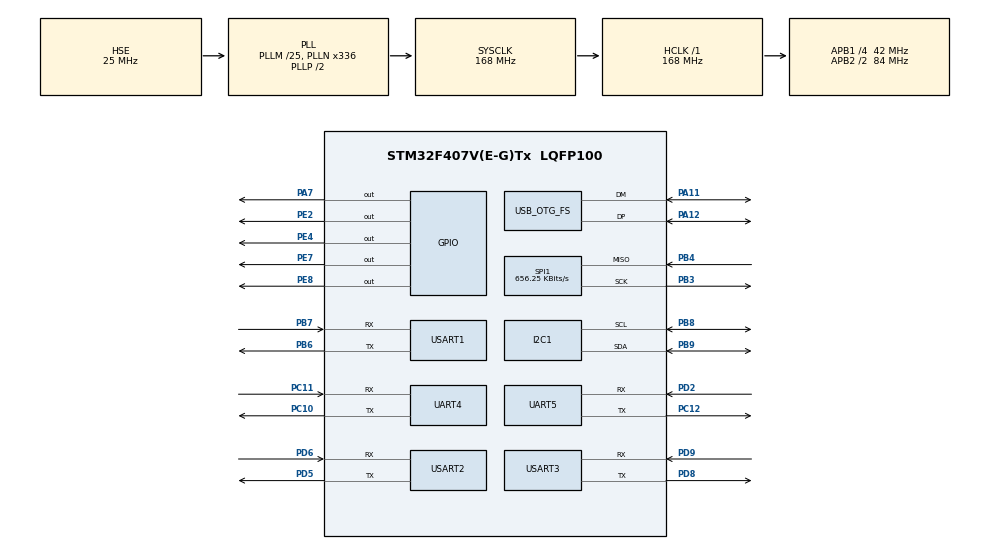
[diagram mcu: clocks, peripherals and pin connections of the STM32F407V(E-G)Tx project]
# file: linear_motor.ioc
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Mcu.Family=STM32F4
Mcu.Name=STM32F407V(E-G)Tx
Mcu.Package=LQFP100
NVIC.OTG_FS_IRQn=true\:0\:0\:false\:false\:true\:false\:true
NVIC.PriorityGroup=NVIC_PRIORITYGROUP_4
NVIC.TIM7_IRQn=true\:0\:0\:false\:false\:true\:true\:true
NVIC.UART4_IRQn=true\:0\:0\:false\:false\:true\:true\:true
NVIC.USART2_IRQn=true\:0\:0\:false\:false\:true\:true\:true
NVIC.USART3_IRQn=true\:0\:0\:false\:false\:true\:true\:true
PA11.Mode=Device_Only
PA11.Signal=USB_OTG_FS_DM
PA12.Mode=Device_Only
PA12.Signal=USB_OTG_FS_DP
PA7.Signal=GPIO_Output
PB3.Mode=RX_Only_Simplex_Unidirect_Master
PB3.Signal=SPI1_SCK
PB4.Mode=RX_Only_Simplex_Unidirect_Master
PB4.Signal=SPI1_MISO
PB6.Mode=Asynchronous
PB6.Signal=USART1_TX
PB7.Mode=Asynchronous
PB7.Signal=USART1_RX
PB8.Mode=I2C
PB8.Signal=I2C1_SCL
PB9.Mode=I2C
PB9.Signal=I2C1_SDA
PC10.Mode=Asynchronous
PC10.Signal=UART4_TX
PC11.Mode=Asynchronous
PC11.Signal=UART4_RX
PC12.Mode=Asynchronous
PC12.Signal=UART5_TX
PD2.Mode=Asynchronous
PD2.Signal=UART5_RX
PD5.Mode=Asynchronous
PD5.Signal=USART2_TX
PD6.GPIO_PuPd=GPIO_PULLUP
PD6.Mode=Asynchronous
PD6.Signal=USART2_RX
PD8.Mode=Asynchronous
PD8.Signal=USART3_TX
PD9.Mode=Asynchronous
PD9.Signal=USART3_RX
PE2.Signal=GPIO_Output
PE4.Signal=GPIO_Output
PE7.Signal=GPIO_Output
PE8.Signal=GPIO_Output
PH0-OSC_IN.Mode=HSE-External-Oscillator
PH0-OSC_IN.Signal=RCC_OSC_IN
PH1-OSC_OUT.Mode=HSE-External-Oscillator
PH1-OSC_OUT.Signal=RCC_OSC_OUT
ProjectManager.HeapSize=0x200
ProjectManager.StackSize=0x400
ProjectManager.TargetToolchain=STM32CubeIDE
RCC.48MHZClocksFreq_Value=48000000
RCC.AHBFreq_Value=168000000
RCC.APB1CLKDivider=RCC_HCLK_DIV4
RCC.APB1Freq_Value=42000000
RCC.APB1TimFreq_Value=84000000
RCC.APB2CLKDivider=RCC_HCLK_DIV2
RCC.APB2Freq_Value=84000000
RCC.APB2TimFreq_Value=168000000
RCC.CortexFreq_Value=168000000
RCC.EnbaleCSS=true
RCC.HCLKFreq_Value=168000000
RCC.HSE_VALUE=25000000
RCC.HSI_VALUE=16000000
RCC.LSE_VALUE=32768
RCC.PLLM=25
RCC.PLLN=336
RCC.PLLQ=7
RCC.SYSCLKFreq_VALUE=168000000
RCC.SYSCLKSource=RCC_SYSCLKSOURCE_PLLCLK
RCC.VCOOutputFreq_Value=336000000
SPI1.BaudRatePrescaler=SPI_BAUDRATEPRESCALER_128
SPI1.CalculateBaudRate=656.25 KBits/s
SPI1.Direction=SPI_DIRECTION_2LINES_RXONLY
SPI1.Mode=SPI_MODE_MASTER
SPI1.VirtualType=VM_MASTER
TIM7.Period=999
TIM7.Prescaler=2099
UART4.VirtualMode=Asynchronous
UART5.VirtualMode=Asynchronous
USART1.Parity=PARITY_EVEN
USART1.VirtualMode=VM_ASYNC
USART1.WordLength=WORDLENGTH_9B
USART2.VirtualMode=VM_ASYNC
USART3.VirtualMode=VM_ASYNC
USB_DEVICE.CLASS_NAME_FS=CDC
USB_DEVICE.MANUFACTURER_STRING-CDC_FS=Cytena BPS
USB_DEVICE.PRODUCT_STRING_CDC_FS=CYTENABPS_SNEST
USB_DEVICE.VirtualMode-CDC_FS=Cdc
USB_DEVICE.VirtualModeFS=Cdc_FS
USB_OTG_FS.VirtualMode=Device_Only
VP_TIM7_VS_ClockSourceINT.Mode=Enable_Timer
VP_USB_DEVICE_VS_USB_DEVICE_CDC_FS.Mode=CDC_FS
board=custom

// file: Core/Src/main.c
/* USER CODE BEGIN Header */
/**
  ******************************************************************************
  * @file           : main.c
  * @brief          : Main program body
  ******************************************************************************
  * @attention
  *
  * <h2><center>&copy; Copyright (c) 2022 STMicroelectronics.
  * All rights reserved.</center></h2>
  *
  * This software component is licensed by ST under Ultimate Liberty license
  * SLA0044, the "License"; You may not use this file except in compliance with
  * the License. You may obtain a copy of the License at:
  *                             www.st.com/SLA0044
  *
  ******************************************************************************
  */
/* USER CODE END Header */
#include "main.h"
#include "usb_device.h"

/* USER CODE BEGIN Includes */
#include "user_main.hpp"
/* USER CODE END Includes */

I2C_HandleTypeDef hi2c1;

SPI_HandleTypeDef hspi1;

TIM_HandleTypeDef htim7;

UART_HandleTypeDef huart4;
UART_HandleTypeDef huart5;
UART_HandleTypeDef huart1;
UART_HandleTypeDef huart2;
UART_HandleTypeDef huart3;

void SystemClock_Config(void);
static void MX_GPIO_Init(void);
static void MX_UART4_Init(void);
static void MX_USART3_UART_Init(void);
static void MX_I2C1_Init(void);
static void MX_SPI1_Init(void);
static void MX_USART1_UART_Init(void);
static void MX_USART2_UART_Init(void);
static void MX_TIM7_Init(void);
static void MX_UART5_Init(void);

int main(void)
{

  /* MCU Configuration--------------------------------------------------------*/

  /* Reset of all peripherals, Initializes the Flash interface and the Systick. */
  HAL_Init();

  /* Configure the system clock */
  SystemClock_Config();

  /* Initialize all configured peripherals */
  MX_GPIO_Init();
  MX_UART4_Init();
  MX_USB_DEVICE_Init();
  MX_USART3_UART_Init();
  MX_I2C1_Init();
  MX_SPI1_Init();
  MX_USART1_UART_Init();
  MX_USART2_UART_Init();
  MX_TIM7_Init();
  MX_UART5_Init();
  /* USER CODE BEGIN 2 */
  user_init();
  /* USER CODE END 2 */

  /* Infinite loop */
  /* USER CODE BEGIN WHILE */
  while (1)
  {
	  user_main();
    /* USER CODE END WHILE */

  }
}

void SystemClock_Config(void)
{
  RCC_OscInitTypeDef RCC_OscInitStruct = {0};
  RCC_ClkInitTypeDef RCC_ClkInitStruct = {0};

  /** Configure the main internal regulator output voltage
  */
  __HAL_RCC_PWR_CLK_ENABLE();
  __HAL_PWR_VOLTAGESCALING_CONFIG(PWR_REGULATOR_VOLTAGE_SCALE1);
  /** Initializes the RCC Oscillators according to the specified parameters
  * in the RCC_OscInitTypeDef structure.
  */
  RCC_OscInitStruct.OscillatorType = RCC_OSCILLATORTYPE_HSE;
  RCC_OscInitStruct.HSEState = RCC_HSE_ON;
  RCC_OscInitStruct.PLL.PLLState = RCC_PLL_ON;
  RCC_OscInitStruct.PLL.PLLSource = RCC_PLLSOURCE_HSE;
  RCC_OscInitStruct.PLL.PLLM = 25;
  RCC_OscInitStruct.PLL.PLLN = 336;
  RCC_OscInitStruct.PLL.PLLP = RCC_PLLP_DIV2;
  RCC_OscInitStruct.PLL.PLLQ = 7;
  if (HAL_RCC_OscConfig(&RCC_OscInitStruct) != HAL_OK)
  {
    Error_Handler();
  }
  /** Initializes the CPU, AHB and APB buses clocks
  */
  RCC_ClkInitStruct.ClockType = RCC_CLOCKTYPE_HCLK|RCC_CLOCKTYPE_SYSCLK
                              |RCC_CLOCKTYPE_PCLK1|RCC_CLOCKTYPE_PCLK2;
  RCC_ClkInitStruct.SYSCLKSource = RCC_SYSCLKSOURCE_PLLCLK;
  RCC_ClkInitStruct.AHBCLKDivider = RCC_SYSCLK_DIV1;
  RCC_ClkInitStruct.APB1CLKDivider = RCC_HCLK_DIV4;
  RCC_ClkInitStruct.APB2CLKDivider = RCC_HCLK_DIV2;

  if (HAL_RCC_ClockConfig(&RCC_ClkInitStruct, FLASH_LATENCY_5) != HAL_OK)
  {
    Error_Handler();
  }
  /** Enables the Clock Security System
  */
  HAL_RCC_EnableCSS();
}

static void MX_I2C1_Init(void)
{

  hi2c1.Instance = I2C1;
  hi2c1.Init.ClockSpeed = 100000;
  hi2c1.Init.DutyCycle = I2C_DUTYCYCLE_2;
  hi2c1.Init.OwnAddress1 = 0;
  hi2c1.Init.AddressingMode = I2C_ADDRESSINGMODE_7BIT;
  hi2c1.Init.DualAddressMode = I2C_DUALADDRESS_DISABLE;
  hi2c1.Init.OwnAddress2 = 0;
  hi2c1.Init.GeneralCallMode = I2C_GENERALCALL_DISABLE;
  hi2c1.Init.NoStretchMode = I2C_NOSTRETCH_DISABLE;
  if (HAL_I2C_Init(&hi2c1) != HAL_OK)
  {
    Error_Handler();
  }

}

static void MX_SPI1_Init(void)
{

  /* SPI1 parameter configuration*/
  hspi1.Instance = SPI1;
  hspi1.Init.Mode = SPI_MODE_MASTER;
  hspi1.Init.Direction = SPI_DIRECTION_2LINES_RXONLY;
  hspi1.Init.DataSize = SPI_DATASIZE_8BIT;
  hspi1.Init.CLKPolarity = SPI_POLARITY_LOW;
  hspi1.Init.CLKPhase = SPI_PHASE_1EDGE;
  hspi1.Init.NSS = SPI_NSS_SOFT;
  hspi1.Init.BaudRatePrescaler = SPI_BAUDRATEPRESCALER_128;
  hspi1.Init.FirstBit = SPI_FIRSTBIT_MSB;
  hspi1.Init.TIMode = SPI_TIMODE_DISABLE;
  hspi1.Init.CRCCalculation = SPI_CRCCALCULATION_DISABLE;
  hspi1.Init.CRCPolynomial = 10;
  if (HAL_SPI_Init(&hspi1) != HAL_OK)
  {
    Error_Handler();
  }

}

static void MX_TIM7_Init(void)
{

  TIM_MasterConfigTypeDef sMasterConfig = {0};

  htim7.Instance = TIM7;
  htim7.Init.Prescaler = 2099;
  htim7.Init.CounterMode = TIM_COUNTERMODE_UP;
  htim7.Init.Period = 999;
  htim7.Init.AutoReloadPreload = TIM_AUTORELOAD_PRELOAD_DISABLE;
  if (HAL_TIM_Base_Init(&htim7) != HAL_OK)
  {
    Error_Handler();
  }
  sMasterConfig.MasterOutputTrigger = TIM_TRGO_RESET;
  sMasterConfig.MasterSlaveMode = TIM_MASTERSLAVEMODE_DISABLE;
  if (HAL_TIMEx_MasterConfigSynchronization(&htim7, &sMasterConfig) != HAL_OK)
  {
    Error_Handler();
  }

}

static void MX_UART4_Init(void)
{

  huart4.Instance = UART4;
  huart4.Init.BaudRate = 115200;
  huart4.Init.WordLength = UART_WORDLENGTH_8B;
  huart4.Init.StopBits = UART_STOPBITS_1;
  huart4.Init.Parity = UART_PARITY_NONE;
  huart4.Init.Mode = UART_MODE_TX_RX;
  huart4.Init.HwFlowCtl = UART_HWCONTROL_NONE;
  huart4.Init.OverSampling = UART_OVERSAMPLING_16;
  if (HAL_UART_Init(&huart4) != HAL_OK)
  {
    Error_Handler();
  }

}

static void MX_UART5_Init(void)
{

  huart5.Instance = UART5;
  huart5.Init.BaudRate = 115200;
  huart5.Init.WordLength = UART_WORDLENGTH_8B;
  huart5.Init.StopBits = UART_STOPBITS_1;
  huart5.Init.Parity = UART_PARITY_NONE;
  huart5.Init.Mode = UART_MODE_TX_RX;
  huart5.Init.HwFlowCtl = UART_HWCONTROL_NONE;
  huart5.Init.OverSampling = UART_OVERSAMPLING_16;
  if (HAL_UART_Init(&huart5) != HAL_OK)
  {
    Error_Handler();
  }

}

static void MX_USART1_UART_Init(void)
{

  huart1.Instance = USART1;
  huart1.Init.BaudRate = 115200;
  huart1.Init.WordLength = UART_WORDLENGTH_9B;
  huart1.Init.StopBits = UART_STOPBITS_1;
  huart1.Init.Parity = UART_PARITY_EVEN;
  huart1.Init.Mode = UART_MODE_TX_RX;
  huart1.Init.HwFlowCtl = UART_HWCONTROL_NONE;
  huart1.Init.OverSampling = UART_OVERSAMPLING_16;
  if (HAL_UART_Init(&huart1) != HAL_OK)
  {
    Error_Handler();
  }

}

static void MX_USART2_UART_Init(void)
{

  huart2.Instance = USART2;
  huart2.Init.BaudRate = 115200;
  huart2.Init.WordLength = UART_WORDLENGTH_8B;
  huart2.Init.StopBits = UART_STOPBITS_1;
  huart2.Init.Parity = UART_PARITY_NONE;
  huart2.Init.Mode = UART_MODE_TX_RX;
  huart2.Init.HwFlowCtl = UART_HWCONTROL_NONE;
  huart2.Init.OverSampling = UART_OVERSAMPLING_16;
  if (HAL_UART_Init(&huart2) != HAL_OK)
  {
    Error_Handler();
  }

}

static void MX_USART3_UART_Init(void)
{

  huart3.Instance = USART3;
  huart3.Init.BaudRate = 115200;
  huart3.Init.WordLength = UART_WORDLENGTH_8B;
  huart3.Init.StopBits = UART_STOPBITS_1;
  huart3.Init.Parity = UART_PARITY_NONE;
  huart3.Init.Mode = UART_MODE_TX_RX;
  huart3.Init.HwFlowCtl = UART_HWCONTROL_NONE;
  huart3.Init.OverSampling = UART_OVERSAMPLING_16;
  if (HAL_UART_Init(&huart3) != HAL_OK)
  {
    Error_Handler();
  }

}

static void MX_GPIO_Init(void)
{
  GPIO_InitTypeDef GPIO_InitStruct = {0};

  /* GPIO Ports Clock Enable */
  __HAL_RCC_GPIOE_CLK_ENABLE();
  __HAL_RCC_GPIOH_CLK_ENABLE();
  __HAL_RCC_GPIOA_CLK_ENABLE();
  __HAL_RCC_GPIOD_CLK_ENABLE();
  __HAL_RCC_GPIOC_CLK_ENABLE();
  __HAL_RCC_GPIOB_CLK_ENABLE();

  /*Configure GPIO pin Output Level */
  HAL_GPIO_WritePin(GPIOE, GPIO_PIN_2|GPIO_PIN_4|GPIO_PIN_7|GPIO_PIN_8, GPIO_PIN_RESET);

  /*Configure GPIO pin Output Level */
  HAL_GPIO_WritePin(GPIOA, GPIO_PIN_7, GPIO_PIN_RESET);

  /*Configure GPIO pins : PE2 PE4 PE7 PE8 */
  GPIO_InitStruct.Pin = GPIO_PIN_2|GPIO_PIN_4|GPIO_PIN_7|GPIO_PIN_8;
  GPIO_InitStruct.Mode = GPIO_MODE_OUTPUT_PP;
  GPIO_InitStruct.Pull = GPIO_NOPULL;
  GPIO_InitStruct.Speed = GPIO_SPEED_FREQ_LOW;
  HAL_GPIO_Init(GPIOE, &GPIO_InitStruct);

  /*Configure GPIO pin : PA7 */
  GPIO_InitStruct.Pin = GPIO_PIN_7;
  GPIO_InitStruct.Mode = GPIO_MODE_OUTPUT_PP;
  GPIO_InitStruct.Pull = GPIO_NOPULL;
  GPIO_InitStruct.Speed = GPIO_SPEED_FREQ_LOW;
  HAL_GPIO_Init(GPIOA, &GPIO_InitStruct);

}

void Error_Handler(void)
{
  __disable_irq();
  while (1)
  {
  }
}

/************************ (C) COPYRIGHT STMicroelectronics *****END OF FILE****/
